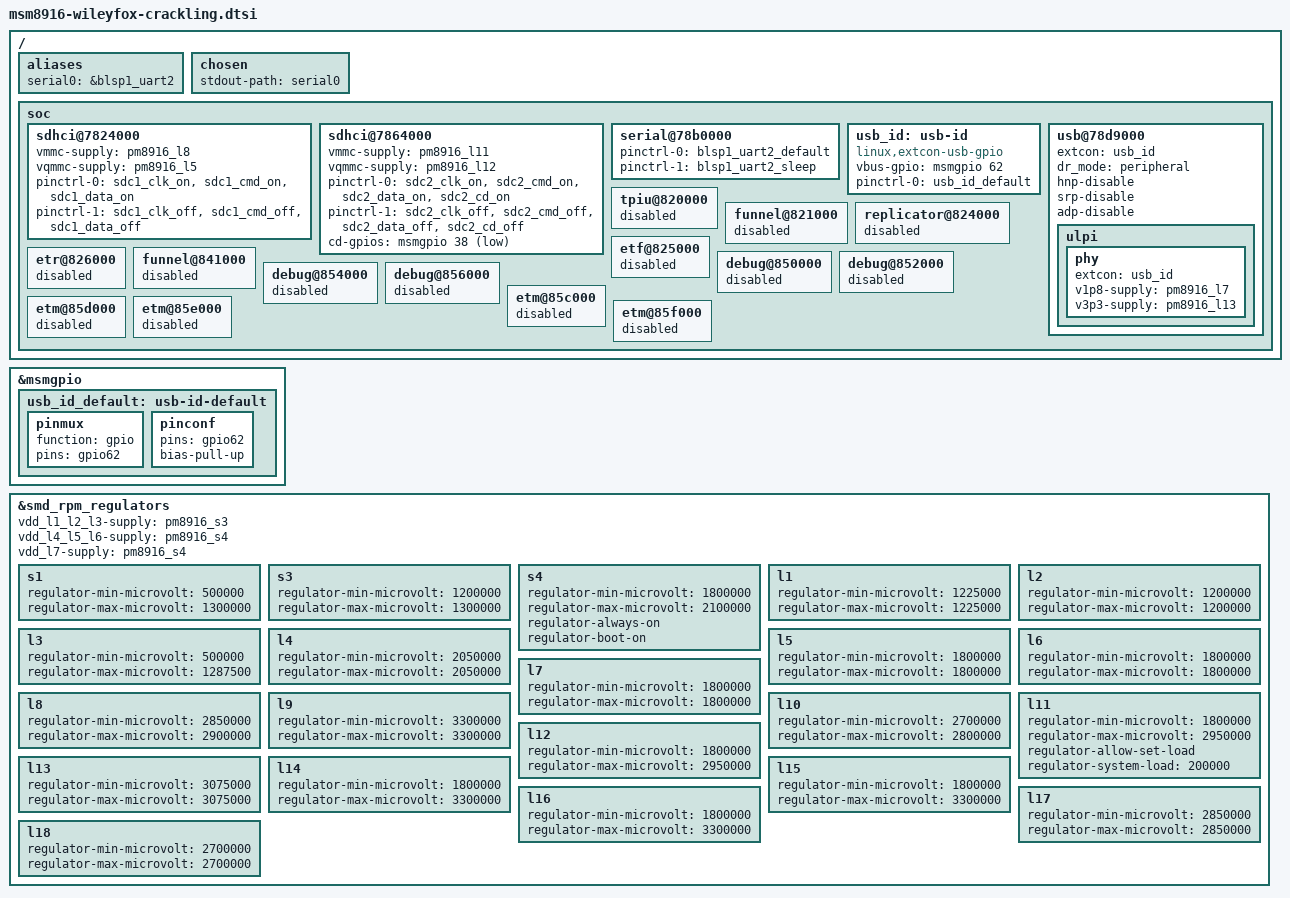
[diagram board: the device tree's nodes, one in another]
// SPDX-License-Identifier: GPL-2.0-only


#include "msm8916.dtsi"
#include "pm8916.dtsi"
#include <dt-bindings/gpio/gpio.h>
#include <dt-bindings/interrupt-controller/irq.h>


//#include "msm8916-samsung-a2015-common-pins.dtsi" // (Looks like muic stuff)



/*
 * grep -nB 1 -A 5 "usb" msm8916* l8150/*
 */


/ {
	aliases {
		serial0 = &blsp1_uart2;
	};

	chosen {
		stdout-path = "serial0";
	};

	soc {
        
        // muic removed.

		sdhci@7824000 {
			status = "okay";

			vmmc-supply = <&pm8916_l8>;
			vqmmc-supply = <&pm8916_l5>;

			pinctrl-names = "default", "sleep";
			pinctrl-0 = <&sdc1_clk_on &sdc1_cmd_on &sdc1_data_on>;
			pinctrl-1 = <&sdc1_clk_off &sdc1_cmd_off &sdc1_data_off>;
		};
        
        

		sdhci@7864000 {
			status = "okay";

			vmmc-supply = <&pm8916_l11>;
			vqmmc-supply = <&pm8916_l12>;

			pinctrl-names = "default", "sleep";
			pinctrl-0 = <&sdc2_clk_on &sdc2_cmd_on &sdc2_data_on &sdc2_cd_on>;
			pinctrl-1 = <&sdc2_clk_off &sdc2_cmd_off &sdc2_data_off &sdc2_cd_off>;

			cd-gpios = <&msmgpio 38 GPIO_ACTIVE_LOW>;
		};

		serial@78b0000 {
			status = "okay";
			pinctrl-names = "default", "sleep";
			pinctrl-0 = <&blsp1_uart2_default>;
			pinctrl-1 = <&blsp1_uart2_sleep>;
		};
        
        // Random NC GPIO choosen
        usb_id: usb-id {
            compatible = "linux,extcon-usb-gpio";
            vbus-gpio = <&msmgpio 62 GPIO_ACTIVE_HIGH>;
            pinctrl-names = "default";
            pinctrl-0 = <&usb_id_default>;
        };

		usb@78d9000 {
			status = "okay";
            extcon = <&usb_id>;
            dr_mode = "peripheral";

			hnp-disable;
			srp-disable;
			adp-disable;

			ulpi {
				phy {
					extcon = <&usb_id>;
					v1p8-supply = <&pm8916_l7>;
					v3p3-supply = <&pm8916_l13>; // L13 should give 3v0 not 3v3 ???
                                                 // But it actually connected to VDD_USBPHY_3P3 so it's ok I guess
				};
			};
		};

		/*
		 * Attempting to enable these devices causes a "synchronous
		 * external abort". Suspected cause is that the debug power
		 * domain is not enabled by default on this device.
		 * Disable these devices for now to avoid the crash.
		 *
		 * See: https://lore.kernel.org/linux-arm-msm/20190618202623.GA53651@gerhold.net/
		 */
		tpiu@820000 { status = "disabled"; };
		funnel@821000 { status = "disabled"; };
		replicator@824000 { status = "disabled"; };
		etf@825000 { status = "disabled"; };
		etr@826000 { status = "disabled"; };
		funnel@841000 { status = "disabled"; };
		debug@850000 { status = "disabled"; };
		debug@852000 { status = "disabled"; };
		debug@854000 { status = "disabled"; };
		debug@856000 { status = "disabled"; };
		etm@85c000 { status = "disabled"; };
		etm@85d000 { status = "disabled"; };
		etm@85e000 { status = "disabled"; };
		etm@85f000 { status = "disabled"; };
	};
};


&msmgpio {
	usb_id_default: usb-id-default {
		pinmux {
			function = "gpio";
			pins = "gpio62";
		};

		pinconf {
			pins = "gpio62";
			bias-pull-up;
		};
	};
};


// https://github.com/LineageOS/android_kernel_cyanogen_msm8916/blob/lineage-16.0/arch/arm/boot/dts/qcom/msm8916-regulator.dtsi

// Values from msm8916-regulator.dtsi Found using
// grep -nB 4 -A 5 "regulator-...-microvolt" msm8916* l8150/*


&smd_rpm_regulators {
	vdd_l1_l2_l3-supply = <&pm8916_s3>;
	vdd_l4_l5_l6-supply = <&pm8916_s4>;
	vdd_l7-supply = <&pm8916_s4>;
    
    // XX: min - default - max - default on
    // Expected usage
    

    // S1: 0v5 - 1v15 - 1v35 - Y
    // MSM IC core (modem, gpu, ...)
	s1 {
		regulator-min-microvolt = <500000>;  // 0v5
		regulator-max-microvolt = <1300000>; // 1v3   Line 119 - corner values ???
	};
    
    // s2 in line 16 ???
    
    // S2: 0v9 - 1v15 - 1v35 - Y
    // A53 application cores

    // S3: 1v25 - 1v3 - 1v35 - Y
    // Analog blocks of WAN, WLAN; Source for L1, L2, L3
	s3 {
		regulator-min-microvolt = <1200000>; // 1v2
		regulator-max-microvolt = <1300000>; // 1v3
	};

    // S4: 1v85 - 2v1 - 2v15 - Y
    // Codec analog; source for L4, L5, L6, L7
	s4 {
		regulator-min-microvolt = <1800000>; // 1v8
		regulator-max-microvolt = <2100000>; // 2v1   <--- line 162

		regulator-always-on;
		regulator-boot-on;
	};
    
    // L1: 1v0 - 1v225 - 1v225 - N
    // WTR low voltage rail
	l1 {
		regulator-min-microvolt = <1225000>; // 1v225
		regulator-max-microvolt = <1225000>;
	};
    
    // L2: 1v2 - 1v15 - 1v2 - Y
    // Memory (lpDDR, eMMC, EBI); MIPI analog rails
	l2 {
		regulator-min-microvolt = <1200000>; // 1v2
		regulator-max-microvolt = <1200000>;
	};

    // L3: 0v75 - 1v2 - 1v35 - Y
    // Modem IC
	l3 {
		regulator-min-microvolt = <500000>;  // 0v5
		regulator-max-microvolt = <1287500>; // 1v2875  Line 189 - corner values ???
	};

    // L4: 1v8 - 2v05 - 2v1 - N
    // WTR, GPS eLNA
	l4 {
		regulator-min-microvolt = <2050000>; // 2v05
		regulator-max-microvolt = <2050000>;
	};

    // L5: 1v8 - 1v8 - 1v8 - Y
    // Codec and memory 1v8 rails
	l5 {
		regulator-min-microvolt = <1800000>; // 1v8
		regulator-max-microvolt = <1800000>;
	};

    // L6: 1v8 - 1v8 - 1v8 - Y
    // Camera, display, transduser 1v8 rails; HK ADC
	l6 {
		regulator-min-microvolt = <1800000>; // 1v8
		regulator-max-microvolt = <1800000>;
	};

    // L7: 1v8 - 1v8 - 1v9 - Y
    // Modem, WTR, BB_CLK driver
	l7 {
		regulator-min-microvolt = <1800000>; // 1v8   Line 247 - have _ao and _so ???
		regulator-max-microvolt = <1800000>;
	};

    // L8: 2v9 - 2v9 - 2v9 - Y
    // eMMC/NAND core
	l8 {
		regulator-min-microvolt = <2850000>; // 2v85
		regulator-max-microvolt = <2900000>; // 2v9
	};

    // L9: 3v3 - 3v3 - 3v3 - N
    // Connectivity IC (WCN36x0)
	l9 {
		regulator-min-microvolt = <3300000>; // 3v3
		regulator-max-microvolt = <3300000>;
	};

    // L10: 2v8-2v7-2v8 - N
    // Cameras analog rails
	l10 {
		regulator-min-microvolt = <2700000>; // 2v7
		regulator-max-microvolt = <2800000>; // 2v8
	};

    // L11: 2v95 - 2v8 - 2v95 - Y
    // SD/MMC card
	l11 {
		regulator-min-microvolt = <1800000>; // 1v8
		regulator-max-microvolt = <2950000>; // 2v95
		regulator-allow-set-load;
		regulator-system-load = <200000>;    // 200 mA ???
	};

    // L12: 1v8 - 2v8 - 2v95 - Y
    // MSM8x16 memory rail for SD
	l12 {
		regulator-min-microvolt = <1800000>; // 1v8
		regulator-max-microvolt = <2950000>; // 2v95
	};

    // L13: 3v075 - 3v075 - 3v075 - Y
    // Codec; USB 3v0 analog rails
	l13 {
		regulator-min-microvolt = <3075000>; // 3v075
		regulator-max-microvolt = <3075000>;
	};

    // L14: 1v8 - 1v8 - 3v3 - N
    // UIM 1
	l14 {
		regulator-min-microvolt = <1800000>; // 1v8
		regulator-max-microvolt = <3300000>; // 3v3
	};

    // L15: 1v8 - 1v8 - 3v3 - N
    // UIM 2
	l15 {
		regulator-min-microvolt = <1800000>; // 1v8
		regulator-max-microvolt = <3300000>; // 3v3
	};
    
    /*
     * "Software Caution:
     * L16 Need to Config to 1.8V and turn on later than L17"
     * 
     * Also it looks NC
     */
    
    // L16: 1v8 - 1v8 - 3v3 - N
    // UIM 3
	l16 {
		regulator-min-microvolt = <1800000>; // 1v8
		regulator-max-microvolt = <3300000>; // 3v3
	};

    // L17: 2v85 - 2v85 - 2v85 - N
    // LCD, transducers and camera  2v85 rails
	l17 {
		regulator-min-microvolt = <2850000>; // 2v85
		regulator-max-microvolt = <2850000>; // <--- Line 365
	};

    // L18: 2v7 - 2v7 - 2v7 - N
    // Qcom RF360
	l18 {
		regulator-min-microvolt = <2700000>; // 2v7
		regulator-max-microvolt = <2700000>;
	};
};
